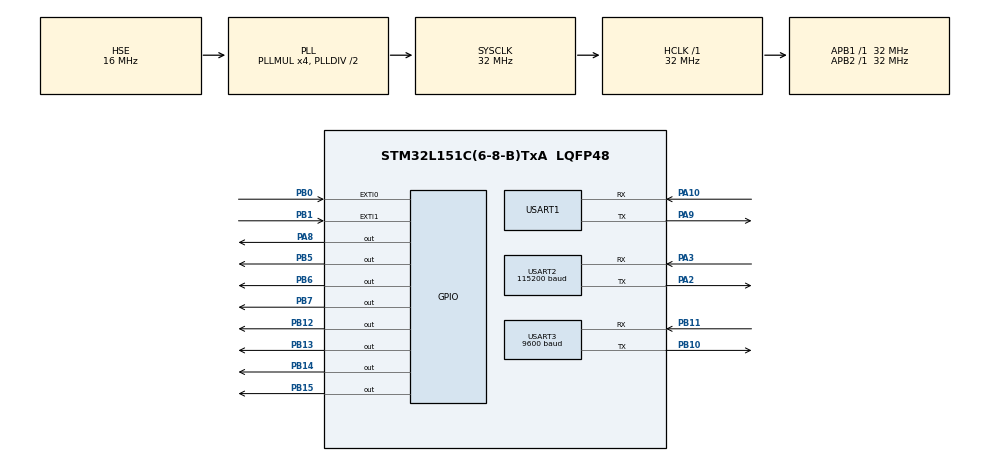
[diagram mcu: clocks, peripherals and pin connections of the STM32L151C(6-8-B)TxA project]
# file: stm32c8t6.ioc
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Dma.MEMTOMEM.4.Direction=DMA_MEMORY_TO_MEMORY
Dma.MEMTOMEM.4.Instance=DMA1_Channel1
Dma.MEMTOMEM.4.MemDataAlignment=DMA_MDATAALIGN_BYTE
Dma.MEMTOMEM.4.MemInc=DMA_MINC_ENABLE
Dma.MEMTOMEM.4.Mode=DMA_NORMAL
Dma.MEMTOMEM.4.PeriphDataAlignment=DMA_PDATAALIGN_BYTE
Dma.MEMTOMEM.4.PeriphInc=DMA_PINC_ENABLE
Dma.MEMTOMEM.4.Priority=DMA_PRIORITY_LOW
Dma.Request0=USART2_RX
Dma.Request1=USART2_TX
Dma.Request2=USART3_RX
Dma.Request3=USART3_TX
Dma.Request4=MEMTOMEM
Dma.Request5=USART1_RX
Dma.Request6=USART1_TX
Dma.USART1_RX.5.Direction=DMA_PERIPH_TO_MEMORY
Dma.USART1_RX.5.Instance=DMA1_Channel5
Dma.USART1_RX.5.MemDataAlignment=DMA_MDATAALIGN_BYTE
Dma.USART1_RX.5.MemInc=DMA_MINC_ENABLE
Dma.USART1_RX.5.Mode=DMA_NORMAL
Dma.USART1_RX.5.PeriphDataAlignment=DMA_PDATAALIGN_BYTE
Dma.USART1_RX.5.PeriphInc=DMA_PINC_DISABLE
Dma.USART1_RX.5.Priority=DMA_PRIORITY_LOW
Dma.USART1_TX.6.Direction=DMA_MEMORY_TO_PERIPH
Dma.USART1_TX.6.Instance=DMA1_Channel4
Dma.USART1_TX.6.MemDataAlignment=DMA_MDATAALIGN_BYTE
Dma.USART1_TX.6.MemInc=DMA_MINC_ENABLE
Dma.USART1_TX.6.Mode=DMA_NORMAL
Dma.USART1_TX.6.PeriphDataAlignment=DMA_PDATAALIGN_BYTE
Dma.USART1_TX.6.PeriphInc=DMA_PINC_DISABLE
Dma.USART1_TX.6.Priority=DMA_PRIORITY_LOW
Dma.USART2_RX.0.Direction=DMA_PERIPH_TO_MEMORY
Dma.USART2_RX.0.Instance=DMA1_Channel6
Dma.USART2_RX.0.MemDataAlignment=DMA_MDATAALIGN_BYTE
Dma.USART2_RX.0.MemInc=DMA_MINC_ENABLE
Dma.USART2_RX.0.Mode=DMA_NORMAL
Dma.USART2_RX.0.PeriphDataAlignment=DMA_PDATAALIGN_BYTE
Dma.USART2_RX.0.PeriphInc=DMA_PINC_DISABLE
Dma.USART2_RX.0.Priority=DMA_PRIORITY_LOW
Dma.USART2_TX.1.Direction=DMA_MEMORY_TO_PERIPH
Dma.USART2_TX.1.Instance=DMA1_Channel7
Dma.USART2_TX.1.MemDataAlignment=DMA_MDATAALIGN_BYTE
Dma.USART2_TX.1.MemInc=DMA_MINC_ENABLE
Dma.USART2_TX.1.Mode=DMA_NORMAL
Dma.USART2_TX.1.PeriphDataAlignment=DMA_PDATAALIGN_BYTE
Dma.USART2_TX.1.PeriphInc=DMA_PINC_DISABLE
Dma.USART2_TX.1.Priority=DMA_PRIORITY_LOW
Dma.USART3_RX.2.Direction=DMA_PERIPH_TO_MEMORY
Dma.USART3_RX.2.Instance=DMA1_Channel3
Dma.USART3_RX.2.MemDataAlignment=DMA_MDATAALIGN_BYTE
Dma.USART3_RX.2.MemInc=DMA_MINC_ENABLE
Dma.USART3_RX.2.Mode=DMA_NORMAL
Dma.USART3_RX.2.PeriphDataAlignment=DMA_PDATAALIGN_BYTE
Dma.USART3_RX.2.PeriphInc=DMA_PINC_DISABLE
Dma.USART3_RX.2.Priority=DMA_PRIORITY_LOW
Dma.USART3_TX.3.Direction=DMA_MEMORY_TO_PERIPH
Dma.USART3_TX.3.Instance=DMA1_Channel2
Dma.USART3_TX.3.MemDataAlignment=DMA_MDATAALIGN_BYTE
Dma.USART3_TX.3.MemInc=DMA_MINC_ENABLE
Dma.USART3_TX.3.Mode=DMA_NORMAL
Dma.USART3_TX.3.PeriphDataAlignment=DMA_PDATAALIGN_BYTE
Dma.USART3_TX.3.PeriphInc=DMA_PINC_DISABLE
Dma.USART3_TX.3.Priority=DMA_PRIORITY_LOW
FREERTOS.Tasks01=defaultTask,0,128,StartDefaultTask,Default,NULL
Mcu.Family=STM32L1
Mcu.Name=STM32L151C(6-8-B)TxA
Mcu.Package=LQFP48
NVIC.DMA1_Channel2_IRQn=true\:5\:0\:false\:false\:true\:true\:false
NVIC.DMA1_Channel3_IRQn=true\:5\:0\:false\:false\:true\:true\:false
NVIC.DMA1_Channel4_IRQn=true\:5\:0\:false\:false\:true\:true\:false
NVIC.DMA1_Channel5_IRQn=true\:5\:0\:false\:false\:true\:true\:false
NVIC.DMA1_Channel6_IRQn=true\:5\:0\:false\:false\:true\:true\:false
NVIC.DMA1_Channel7_IRQn=true\:5\:0\:false\:false\:true\:true\:false
NVIC.EXTI0_IRQn=true\:5\:0\:false\:false\:true\:true\:true
NVIC.EXTI1_IRQn=true\:5\:0\:false\:false\:true\:true\:true
NVIC.PriorityGroup=NVIC_PRIORITYGROUP_4
NVIC.TIM2_IRQn=true\:0\:0\:false\:false\:true\:false\:false
NVIC.TimeBase=TIM2_IRQn
NVIC.TimeBaseIP=TIM2
NVIC.USART1_IRQn=true\:5\:0\:false\:false\:true\:true\:true
NVIC.USART2_IRQn=true\:5\:0\:false\:false\:true\:true\:true
NVIC.USART3_IRQn=true\:5\:0\:false\:false\:true\:true\:true
PA10.Mode=Asynchronous
PA10.Signal=USART1_RX
PA2.Mode=Asynchronous
PA2.Signal=USART2_TX
PA3.Mode=Asynchronous
PA3.Signal=USART2_RX
PA8.Signal=GPIO_Output
PA9.Mode=Asynchronous
PA9.Signal=USART1_TX
PB0.GPIO_ModeDefaultEXTI=GPIO_MODE_IT_RISING_FALLING
PB0.Signal=GPXTI0
PB1.GPIO_ModeDefaultEXTI=GPIO_MODE_IT_RISING_FALLING
PB1.Signal=GPXTI1
PB10.Mode=Asynchronous
PB10.Signal=USART3_TX
PB11.Mode=Asynchronous
PB11.Signal=USART3_RX
PB12.GPIO_PuPd=GPIO_NOPULL
PB12.Signal=GPIO_Output
PB13.Signal=GPIO_Output
PB14.Signal=GPIO_Output
PB15.Signal=GPIO_Output
PB5.Signal=GPIO_Output
PB6.Signal=GPIO_Output
PB7.Signal=GPIO_Output
PC14-OSC32_IN.Mode=LSE-External-Oscillator
PC14-OSC32_IN.Signal=RCC_OSC32_IN
PC15-OSC32_OUT.Mode=LSE-External-Oscillator
PC15-OSC32_OUT.Signal=RCC_OSC32_OUT
PH0-OSC_IN.Mode=HSE-External-Oscillator
PH0-OSC_IN.Signal=RCC_OSC_IN
PH1-OSC_OUT.Mode=HSE-External-Oscillator
PH1-OSC_OUT.Signal=RCC_OSC_OUT
ProjectManager.HeapSize=0x200
ProjectManager.StackSize=0x400
ProjectManager.TargetToolchain=MDK-ARM V5
RCC.48MHZClocksFreq_Value=32000000
RCC.AHBFreq_Value=32000000
RCC.APB1Freq_Value=32000000
RCC.APB1TimFreq_Value=32000000
RCC.APB2Freq_Value=32000000
RCC.APB2TimFreq_Value=32000000
RCC.HCLKFreq_Value=32000000
RCC.HSE_VALUE=16000000
RCC.HSI_VALUE=16000000
RCC.MSI_VALUE=2097000
RCC.PLLMUL=RCC_PLL_MUL4
RCC.PLLSourceVirtual=RCC_PLLSOURCE_HSE
RCC.SYSCLKFreq_VALUE=32000000
RCC.SYSCLKSource=RCC_SYSCLKSOURCE_PLLCLK
RCC.VCOOutputFreq_Value=64000000
USART1.VirtualMode=VM_ASYNC
USART2.BaudRate=115200
USART2.VirtualMode=VM_ASYNC
USART3.BaudRate=9600
USART3.VirtualMode=VM_ASYNC
VP_FREERTOS_VS_ENABLE.Mode=Enabled
VP_SYS_VS_tim2.Mode=TIM2
board=stm32c8t6

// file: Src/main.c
/**
  ******************************************************************************
  * @file           : main.c
  * @brief          : Main program body
  ******************************************************************************
  * This notice applies to any and all portions of this file
  * that are not between comment pairs USER CODE BEGIN and
  * USER CODE END. Other portions of this file, whether
  * inserted by the user or by software development tools
  * are owned by their respective copyright owners.
  *
  * Copyright (c) 2018 STMicroelectronics International N.V.
  * All rights reserved.
  *
  * Redistribution and use in source and binary forms, with or without
  * modification, are permitted, provided that the following conditions are met:
  *
  * 1. Redistribution of source code must retain the above copyright notice,
  *    this list of conditions and the following disclaimer.
  * 2. Redistributions in binary form must reproduce the above copyright notice,
  *    this list of conditions and the following disclaimer in the documentation
  *    and/or other materials provided with the distribution.
  * 3. Neither the name of STMicroelectronics nor the names of other
  *    contributors to this software may be used to endorse or promote products
  *    derived from this software without specific written permission.
  * 4. This software, including modifications and/or derivative works of this
  *    software, must execute solely and exclusively on microcontroller or
  *    microprocessor devices manufactured by or for STMicroelectronics.
  * 5. Redistribution and use of this software other than as permitted under
  *    this license is void and will automatically terminate your rights under
  *    this license.
  *
  * THIS SOFTWARE IS PROVIDED BY STMICROELECTRONICS AND CONTRIBUTORS "AS IS"
  * AND ANY EXPRESS, IMPLIED OR STATUTORY WARRANTIES, INCLUDING, BUT NOT
  * LIMITED TO, THE IMPLIED WARRANTIES OF MERCHANTABILITY, FITNESS FOR A
  * PARTICULAR PURPOSE AND NON-INFRINGEMENT OF THIRD PARTY INTELLECTUAL PROPERTY
  * RIGHTS ARE DISCLAIMED TO THE FULLEST EXTENT PERMITTED BY LAW. IN NO EVENT
  * SHALL STMICROELECTRONICS OR CONTRIBUTORS BE LIABLE FOR ANY DIRECT, INDIRECT,
  * INCIDENTAL, SPECIAL, EXEMPLARY, OR CONSEQUENTIAL DAMAGES (INCLUDING, BUT NOT
  * LIMITED TO, PROCUREMENT OF SUBSTITUTE GOODS OR SERVICES; LOSS OF USE, DATA,
  * OR PROFITS; OR BUSINESS INTERRUPTION) HOWEVER CAUSED AND ON ANY THEORY OF
  * LIABILITY, WHETHER IN CONTRACT, STRICT LIABILITY, OR TORT (INCLUDING
  * NEGLIGENCE OR OTHERWISE) ARISING IN ANY WAY OUT OF THE USE OF THIS SOFTWARE,
  * EVEN IF ADVISED OF THE POSSIBILITY OF SUCH DAMAGE.
  *
  ******************************************************************************
  */
#include "main.h"
#include "stm32l1xx_hal.h"
#include "cmsis_os.h"
#include "application.h"
#include "user_define.h"

UART_HandleTypeDef huart1;
UART_HandleTypeDef huart2;
UART_HandleTypeDef huart3;
DMA_HandleTypeDef hdma_usart1_rx;
DMA_HandleTypeDef hdma_usart1_tx;
DMA_HandleTypeDef hdma_usart2_rx;
DMA_HandleTypeDef hdma_usart2_tx;
DMA_HandleTypeDef hdma_usart3_rx;
DMA_HandleTypeDef hdma_usart3_tx;

DMA_HandleTypeDef hdma_memtomem_dma1_channel1;
osThreadId defaultTaskHandle;

/* USER CODE BEGIN PV */
/* Private variables ---------------------------------------------------------*/

/* USER CODE END PV */

void SystemClock_Config(void);
static void MX_GPIO_Init(void);
static void MX_DMA_Init(void);
static void MX_USART1_UART_Init(void);
static void MX_USART2_UART_Init(void);
static void MX_USART3_UART_Init(void);
void StartDefaultTask(void const * argument);

//关闭所有中断
void INTX_DISABLE(void)
{
	__ASM volatile("cpsid i");
}
//开启所有中断
void INTX_ENABLE(void)
{
	__ASM volatile("cpsie i");
}

/* USER CODE BEGIN PFP */
/* Private function prototypes -----------------------------------------------*/

/* USER CODE END PFP */

int main(void)
{

  /* MCU Configuration----------------------------------------------------------*/

  /* Reset of all peripherals, Initializes the Flash interface and the Systick. */
  HAL_Init();

  /* Configure the system clock */
  SystemClock_Config();

  /* Initialize all configured peripherals */
  MX_GPIO_Init();
  MX_DMA_Init();
  MX_USART1_UART_Init();
  MX_USART2_UART_Init();
  MX_USART3_UART_Init();

  /* Create the thread(s) */
  /* definition and creation of defaultTask */
  osThreadDef(defaultTask, StartDefaultTask, osPriorityNormal, 0, 64);
  defaultTaskHandle = osThreadCreate(osThread(defaultTask), NULL);

	application_start();

  /* Start scheduler */
   osKernelStart();

  /* We should never get here as control is now taken by the scheduler */

  /* Infinite loop */
  while (1)
  {

  }

}

void SystemClock_Config(void)
{

  RCC_OscInitTypeDef RCC_OscInitStruct;
  RCC_ClkInitTypeDef RCC_ClkInitStruct;

    /**Configure the main internal regulator output voltage
    */
  __HAL_PWR_VOLTAGESCALING_CONFIG(PWR_REGULATOR_VOLTAGE_SCALE1);

    /**Initializes the CPU, AHB and APB busses clocks
    */
  RCC_OscInitStruct.OscillatorType = RCC_OSCILLATORTYPE_HSE;
  RCC_OscInitStruct.HSEState = RCC_HSE_ON;
  RCC_OscInitStruct.PLL.PLLState = RCC_PLL_ON;
  RCC_OscInitStruct.PLL.PLLSource = RCC_PLLSOURCE_HSE;
  RCC_OscInitStruct.PLL.PLLMUL = RCC_PLL_MUL4;
  RCC_OscInitStruct.PLL.PLLDIV = RCC_PLL_DIV2;
  if (HAL_RCC_OscConfig(&RCC_OscInitStruct) != HAL_OK)
  {
    _Error_Handler(__FILE__, __LINE__);
  }

    /**Initializes the CPU, AHB and APB busses clocks
    */
  RCC_ClkInitStruct.ClockType = RCC_CLOCKTYPE_HCLK|RCC_CLOCKTYPE_SYSCLK
                              |RCC_CLOCKTYPE_PCLK1|RCC_CLOCKTYPE_PCLK2;
  RCC_ClkInitStruct.SYSCLKSource = RCC_SYSCLKSOURCE_PLLCLK;
  RCC_ClkInitStruct.AHBCLKDivider = RCC_SYSCLK_DIV1;
  RCC_ClkInitStruct.APB1CLKDivider = RCC_HCLK_DIV1;
  RCC_ClkInitStruct.APB2CLKDivider = RCC_HCLK_DIV1;

  if (HAL_RCC_ClockConfig(&RCC_ClkInitStruct, FLASH_LATENCY_1) != HAL_OK)
  {
    _Error_Handler(__FILE__, __LINE__);
  }

    /**Configure the Systick interrupt time
    */
  HAL_SYSTICK_Config(HAL_RCC_GetHCLKFreq()/1000);

    /**Configure the Systick
    */
  HAL_SYSTICK_CLKSourceConfig(SYSTICK_CLKSOURCE_HCLK);

  /* SysTick_IRQn interrupt configuration */
  HAL_NVIC_SetPriority(SysTick_IRQn, 15, 0);
}

/* USART1 init function */
static void MX_USART1_UART_Init(void)
{

  huart1.Instance = USART1;
  huart1.Init.BaudRate = 115200;
  huart1.Init.WordLength = UART_WORDLENGTH_8B;
  huart1.Init.StopBits = UART_STOPBITS_1;
  huart1.Init.Parity = UART_PARITY_NONE;
  huart1.Init.Mode = UART_MODE_TX_RX;
  huart1.Init.HwFlowCtl = UART_HWCONTROL_NONE;
  huart1.Init.OverSampling = UART_OVERSAMPLING_16;
  if (HAL_UART_Init(&huart1) != HAL_OK)
  {
    _Error_Handler(__FILE__, __LINE__);
  }

}

/* USART2 init function */
static void MX_USART2_UART_Init(void)
{

  huart2.Instance = USART2;
  huart2.Init.BaudRate = 115200;
  huart2.Init.WordLength = UART_WORDLENGTH_8B;
  huart2.Init.StopBits = UART_STOPBITS_1;
  huart2.Init.Parity = UART_PARITY_NONE;
  huart2.Init.Mode = UART_MODE_TX_RX;
  huart2.Init.HwFlowCtl = UART_HWCONTROL_NONE;
  huart2.Init.OverSampling = UART_OVERSAMPLING_16;
  if (HAL_UART_Init(&huart2) != HAL_OK)
  {
    _Error_Handler(__FILE__, __LINE__);
  }

}

/* USART3 init function */
static void MX_USART3_UART_Init(void)
{

  huart3.Instance = USART3;
  huart3.Init.BaudRate = 9600;
  huart3.Init.WordLength = UART_WORDLENGTH_8B;
  huart3.Init.StopBits = UART_STOPBITS_1;
  huart3.Init.Parity = UART_PARITY_NONE;
  huart3.Init.Mode = UART_MODE_TX_RX;
  huart3.Init.HwFlowCtl = UART_HWCONTROL_NONE;
  huart3.Init.OverSampling = UART_OVERSAMPLING_16;
  if (HAL_UART_Init(&huart3) != HAL_OK)
  {
    _Error_Handler(__FILE__, __LINE__);
  }

}

static void MX_DMA_Init(void)
{
  /* DMA controller clock enable */
  __HAL_RCC_DMA1_CLK_ENABLE();

  /* Configure DMA request hdma_memtomem_dma1_channel1 on DMA1_Channel1 */
  hdma_memtomem_dma1_channel1.Instance = DMA1_Channel1;
  hdma_memtomem_dma1_channel1.Init.Direction = DMA_MEMORY_TO_MEMORY;
  hdma_memtomem_dma1_channel1.Init.PeriphInc = DMA_PINC_ENABLE;
  hdma_memtomem_dma1_channel1.Init.MemInc = DMA_MINC_ENABLE;
  hdma_memtomem_dma1_channel1.Init.PeriphDataAlignment = DMA_PDATAALIGN_BYTE;
  hdma_memtomem_dma1_channel1.Init.MemDataAlignment = DMA_MDATAALIGN_BYTE;
  hdma_memtomem_dma1_channel1.Init.Mode = DMA_NORMAL;
  hdma_memtomem_dma1_channel1.Init.Priority = DMA_PRIORITY_LOW;
  if (HAL_DMA_Init(&hdma_memtomem_dma1_channel1) != HAL_OK)
  {
    _Error_Handler(__FILE__, __LINE__);
  }

  /* DMA interrupt init */
  /* DMA1_Channel2_IRQn interrupt configuration */
  HAL_NVIC_SetPriority(DMA1_Channel2_IRQn, 5, 0);
  HAL_NVIC_EnableIRQ(DMA1_Channel2_IRQn);
  /* DMA1_Channel3_IRQn interrupt configuration */
  HAL_NVIC_SetPriority(DMA1_Channel3_IRQn, 5, 0);
  HAL_NVIC_EnableIRQ(DMA1_Channel3_IRQn);
  /* DMA1_Channel4_IRQn interrupt configuration */
  HAL_NVIC_SetPriority(DMA1_Channel4_IRQn, 5, 0);
  HAL_NVIC_EnableIRQ(DMA1_Channel4_IRQn);
  /* DMA1_Channel5_IRQn interrupt configuration */
  HAL_NVIC_SetPriority(DMA1_Channel5_IRQn, 5, 0);
  HAL_NVIC_EnableIRQ(DMA1_Channel5_IRQn);
  /* DMA1_Channel6_IRQn interrupt configuration */
  HAL_NVIC_SetPriority(DMA1_Channel6_IRQn, 5, 0);
  HAL_NVIC_EnableIRQ(DMA1_Channel6_IRQn);
  /* DMA1_Channel7_IRQn interrupt configuration */
  HAL_NVIC_SetPriority(DMA1_Channel7_IRQn, 5, 0);
  HAL_NVIC_EnableIRQ(DMA1_Channel7_IRQn);

}

/** Configure pins as
        * Analog
        * Input
        * Output
        * EVENT_OUT
        * EXTI
*/
static void MX_GPIO_Init(void)
{

  GPIO_InitTypeDef GPIO_InitStruct;

  /* GPIO Ports Clock Enable */
  __HAL_RCC_GPIOC_CLK_ENABLE();
  __HAL_RCC_GPIOH_CLK_ENABLE();
  __HAL_RCC_GPIOA_CLK_ENABLE();
  __HAL_RCC_GPIOB_CLK_ENABLE();

  /*Configure GPIO pin Output Level */
  HAL_GPIO_WritePin(GPIOB, GPIO_PIN_12|GPIO_PIN_13|GPIO_PIN_14|GPIO_PIN_15
                          |GPIO_PIN_5|GPIO_PIN_6|GPIO_PIN_7, GPIO_PIN_RESET);

  /*Configure GPIO pin Output Level */
  HAL_GPIO_WritePin(GPIOA, GPIO_PIN_8, GPIO_PIN_RESET);

  /*Configure GPIO pins : PB0 PB1 */
  GPIO_InitStruct.Pin = GPIO_PIN_0|GPIO_PIN_1;
  GPIO_InitStruct.Mode = GPIO_MODE_IT_RISING_FALLING;
  GPIO_InitStruct.Pull = GPIO_NOPULL;
  HAL_GPIO_Init(GPIOB, &GPIO_InitStruct);

  /*Configure GPIO pins : PB12 PB13 PB14 PB15
                           PB5 PB6 PB7 */
  GPIO_InitStruct.Pin = GPIO_PIN_12|GPIO_PIN_13|GPIO_PIN_14|GPIO_PIN_15
                          |GPIO_PIN_5|GPIO_PIN_6|GPIO_PIN_7;
  GPIO_InitStruct.Mode = GPIO_MODE_OUTPUT_PP;
  GPIO_InitStruct.Pull = GPIO_NOPULL;
  GPIO_InitStruct.Speed = GPIO_SPEED_FREQ_LOW;
  HAL_GPIO_Init(GPIOB, &GPIO_InitStruct);

  /*Configure GPIO pin : PA8 */
  GPIO_InitStruct.Pin = GPIO_PIN_8;
  GPIO_InitStruct.Mode = GPIO_MODE_OUTPUT_PP;
  GPIO_InitStruct.Pull = GPIO_NOPULL;
  GPIO_InitStruct.Speed = GPIO_SPEED_FREQ_LOW;
  HAL_GPIO_Init(GPIOA, &GPIO_InitStruct);

  /* EXTI interrupt init*/
  HAL_NVIC_SetPriority(EXTI0_IRQn, 5, 0);
  HAL_NVIC_EnableIRQ(EXTI0_IRQn);

  HAL_NVIC_SetPriority(EXTI1_IRQn, 5, 0);
  HAL_NVIC_EnableIRQ(EXTI1_IRQn);

}

/* StartDefaultTask function */
void StartDefaultTask(void const * argument)
{

  /* USER CODE BEGIN 5 */
  /* Infinite loop */
  for(;;)
  {
		osDelay(1000);
		//HAL_GPIO_WritePin(GPIOB, GPIO_PIN_1, GPIO_PIN_SET);
		//osDelay(1000);
		//HAL_GPIO_WritePin(GPIOB, GPIO_PIN_1, GPIO_PIN_RESET);
		//osDelay(1000);
	  //osDelay(1);
	  //osDelay(1);
	  //osDelay(1);

  }
  /* USER CODE END 5 */
}

void HAL_TIM_PeriodElapsedCallback(TIM_HandleTypeDef *htim)
{
  if (htim->Instance == TIM2) {
    HAL_IncTick();
  }
}

void _Error_Handler(char *file, int line)
{
  while(1)
  {
  }
}

/************************ (C) COPYRIGHT STMicroelectronics *****END OF FILE****/
